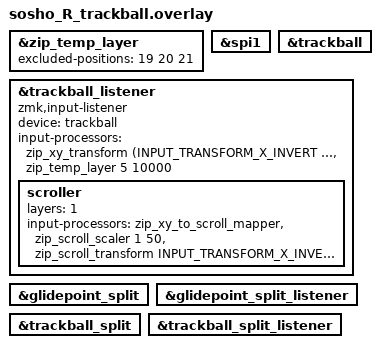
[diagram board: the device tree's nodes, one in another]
#include "sosho_R.dtsi"

&zip_temp_layer {
	// 下記（J, K, L）以外のキーを押下でマウスレイヤーを抜ける
    excluded-positions = <
        19
        20
        21
    >;
	// キー入力から0.2秒間はマウスレイヤーに移動しない（誤作動防止）
	//require-prior-idle-ms = <200>;
};

&spi1 { status = "okay"; };
&trackball { status = "okay"; };
&trackball_listener {
	status = "okay";
	compatible = "zmk,input-listener";
	device = <&trackball>;

	// 最後のマウス操作から10秒間マウスレイヤーを有効にする
	input-processors = <
		&zip_xy_transform (INPUT_TRANSFORM_X_INVERT | INPUT_TRANSFORM_Y_INVERT)
		&zip_temp_layer 5 10000
	>;

	// カーソル移動をスクロールに変更
	scroller {
        layers = <1>;
        input-processors = <
            &zip_xy_to_scroll_mapper
            &zip_scroll_scaler 1 50
			&zip_scroll_transform INPUT_TRANSFORM_X_INVERT
        >;
    };
};

&glidepoint_split { status = "okay"; };
&glidepoint_split_listener {
    status = "okay";
/* input-processors = <&zip_xy_scaler 2 1>; */
};

&trackball_split { status = "okay"; };
&trackball_split_listener { status = "okay"; };
